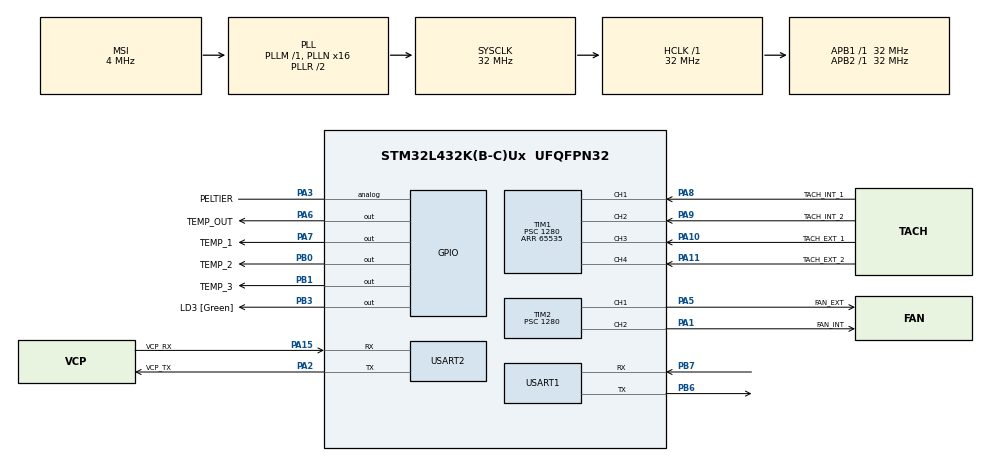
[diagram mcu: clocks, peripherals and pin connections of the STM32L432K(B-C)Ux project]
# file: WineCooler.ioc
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Mcu.Family=STM32L4
Mcu.Name=STM32L432K(B-C)Ux
Mcu.Package=UFQFPN32
NVIC.PriorityGroup=NVIC_PRIORITYGROUP_4
NVIC.TIM2_IRQn=true\:0\:0\:false\:false\:true\:true
NVIC.TIM6_DAC_IRQn=true\:0\:0\:false\:false\:true\:false
NVIC.TimeBase=TIM6_DAC_IRQn
NVIC.TimeBaseIP=TIM6
NVIC.USART1_IRQn=true\:0\:0\:false\:false\:true\:true
PA0.GPIO_Label=MCO [High speed clock in]
PA0.Mode=HSE-External-Clock-Source-for-LittleOrca
PA0.Signal=RCC_CK_IN
PA1.GPIO_Label=FAN_INT
PA1.GPIO_PuPd=GPIO_PULLUP
PA1.GPIO_Speed=GPIO_SPEED_FREQ_VERY_HIGH
PA1.Signal=S_TIM2_CH2
PA10.GPIO_Label=TACH_EXT_1
PA10.GPIO_Speed=GPIO_SPEED_FREQ_VERY_HIGH
PA10.Signal=S_TIM1_CH3
PA11.GPIO_Label=TACH_EXT_2
PA11.GPIO_Speed=GPIO_SPEED_FREQ_VERY_HIGH
PA11.Signal=S_TIM1_CH4
PA13\ (JTMS-SWDIO).GPIO_Label=SWDIO
PA13\ (JTMS-SWDIO).Mode=Serial_Wire
PA13\ (JTMS-SWDIO).Signal=SYS_JTMS-SWDIO
PA14\ (JTCK-SWCLK).GPIO_Label=SWCLK
PA14\ (JTCK-SWCLK).Mode=Serial_Wire
PA14\ (JTCK-SWCLK).Signal=SYS_JTCK-SWCLK
PA15\ (JTDI).GPIO_Label=VCP_RX
PA15\ (JTDI).Mode=Asynchronous
PA15\ (JTDI).Signal=USART2_RX
PA2.GPIO_Label=VCP_TX
PA2.Mode=Asynchronous
PA2.Signal=USART2_TX
PA3.GPIO_Label=PELTIER
PA3.Signal=GPIO_Analog
PA5.GPIO_Label=FAN_EXT
PA5.GPIO_PuPd=GPIO_PULLUP
PA5.GPIO_Speed=GPIO_SPEED_FREQ_VERY_HIGH
PA5.Signal=S_TIM2_CH1
PA6.GPIO_Label=TEMP_OUT
PA6.GPIO_Speed=GPIO_SPEED_FREQ_VERY_HIGH
PA6.Signal=GPIO_Output
PA7.GPIO_Label=TEMP_1
PA7.GPIO_Speed=GPIO_SPEED_FREQ_VERY_HIGH
PA7.Signal=GPIO_Output
PA8.GPIO_Label=TACH_INT_1
PA8.GPIO_Speed=GPIO_SPEED_FREQ_VERY_HIGH
PA8.Signal=S_TIM1_CH1
PA9.GPIO_Label=TACH_INT_2
PA9.GPIO_Speed=GPIO_SPEED_FREQ_VERY_HIGH
PA9.Signal=S_TIM1_CH2
PB0.GPIO_Label=TEMP_2
PB0.GPIO_Speed=GPIO_SPEED_FREQ_VERY_HIGH
PB0.Signal=GPIO_Output
PB1.GPIO_Label=TEMP_3
PB1.GPIO_Speed=GPIO_SPEED_FREQ_VERY_HIGH
PB1.Signal=GPIO_Output
PB3\ (JTDO-TRACESWO).GPIO_Label=LD3 [Green]
PB3\ (JTDO-TRACESWO).Signal=GPIO_Output
PB6.Mode=Asynchronous
PB6.Signal=USART1_TX
PB7.Mode=Asynchronous
PB7.Signal=USART1_RX
PC14-OSC32_IN\ (PC14).Mode=LSE-External-Oscillator
PC14-OSC32_IN\ (PC14).Signal=RCC_OSC32_IN
PC15-OSC32_OUT\ (PC15).Mode=LSE-External-Oscillator
PC15-OSC32_OUT\ (PC15).Signal=RCC_OSC32_OUT
ProjectManager.HeapSize=0x200
ProjectManager.StackSize=0x400
ProjectManager.TargetToolchain=SW4STM32
RCC.AHBFreq_Value=32000000
RCC.APB1Freq_Value=32000000
RCC.APB1TimFreq_Value=32000000
RCC.APB2Freq_Value=32000000
RCC.APB2TimFreq_Value=32000000
RCC.CortexFreq_Value=32000000
RCC.HCLKFreq_Value=32000000
RCC.HSE_VALUE=8000000
RCC.HSI16_VALUE=16000000
RCC.HSI48_VALUE=48000000
RCC.HSI_VALUE=16000000
RCC.MSI_VALUE=4000000
RCC.PLLMUL=RCC_PLLMUL_4
RCC.PLLN=16
RCC.SYSCLKFreq_VALUE=32000000
RCC.SYSCLKSource=RCC_SYSCLKSOURCE_PLLCLK
RCC.VCOOutputFreq_Value=64000000
SH.S_TIM1_CH1.0=TIM1_CH1,Input_Capture1_from_TI1
SH.S_TIM1_CH2.0=TIM1_CH2,Input_Capture2_from_TI2
SH.S_TIM1_CH3.0=TIM1_CH3,Input_Capture3_from_TI3
SH.S_TIM1_CH4.0=TIM1_CH4,Input_Capture4_from_TI4
SH.S_TIM2_CH1.0=TIM2_CH1,PWM Generation1 CH1
SH.S_TIM2_CH2.0=TIM2_CH2,PWM Generation2 CH2
TIM1.Channel-Input_Capture1_from_TI1=TIM_CHANNEL_1
TIM1.Channel-Input_Capture2_from_TI2=TIM_CHANNEL_2
TIM1.Channel-Input_Capture3_from_TI3=TIM_CHANNEL_3
TIM1.Channel-Input_Capture4_from_TI4=TIM_CHANNEL_4
TIM1.Period=65535
TIM1.Prescaler=1280
TIM2.Channel-PWM\ Generation1\ CH1=TIM_CHANNEL_1
TIM2.Channel-PWM\ Generation2\ CH2=TIM_CHANNEL_2
TIM2.OCFastMode_PWM-PWM\ Generation1\ CH1=TIM_OCFAST_ENABLE
TIM2.OCFastMode_PWM-PWM\ Generation2\ CH2=TIM_OCFAST_ENABLE
TIM2.Period=1000
TIM2.Prescaler=1280
TIM2.Pulse-PWM\ Generation1\ CH1=800
TIM2.Pulse-PWM\ Generation2\ CH2=800
USART1.VirtualMode-Asynchronous=VM_ASYNC
USART2.VirtualMode-Asynchronous=VM_ASYNC
VP_SYS_VS_tim6.Mode=TIM6
VP_TIM1_VS_ClockSourceINT.Mode=Internal
VP_TIM2_VS_ClockSourceINT.Mode=Internal
board=NUCLEO-L432KC

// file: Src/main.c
/**
  ******************************************************************************
  * @file           : main.c
  * @brief          : Main program body
  ******************************************************************************
  ** This notice applies to any and all portions of this file
  * that are not between comment pairs USER CODE BEGIN and
  * USER CODE END. Other portions of this file, whether
  * inserted by the user or by software development tools
  * are owned by their respective copyright owners.
  *
  * COPYRIGHT(c) 2018 STMicroelectronics
  *
  * Redistribution and use in source and binary forms, with or without modification,
  * are permitted provided that the following conditions are met:
  *   1. Redistributions of source code must retain the above copyright notice,
  *      this list of conditions and the following disclaimer.
  *   2. Redistributions in binary form must reproduce the above copyright notice,
  *      this list of conditions and the following disclaimer in the documentation
  *      and/or other materials provided with the distribution.
  *   3. Neither the name of STMicroelectronics nor the names of its contributors
  *      may be used to endorse or promote products derived from this software
  *      without specific prior written permission.
  *
  * THIS SOFTWARE IS PROVIDED BY THE COPYRIGHT HOLDERS AND CONTRIBUTORS "AS IS"
  * AND ANY EXPRESS OR IMPLIED WARRANTIES, INCLUDING, BUT NOT LIMITED TO, THE
  * IMPLIED WARRANTIES OF MERCHANTABILITY AND FITNESS FOR A PARTICULAR PURPOSE ARE
  * DISCLAIMED. IN NO EVENT SHALL THE COPYRIGHT HOLDER OR CONTRIBUTORS BE LIABLE
  * FOR ANY DIRECT, INDIRECT, INCIDENTAL, SPECIAL, EXEMPLARY, OR CONSEQUENTIAL
  * DAMAGES (INCLUDING, BUT NOT LIMITED TO, PROCUREMENT OF SUBSTITUTE GOODS OR
  * SERVICES; LOSS OF USE, DATA, OR PROFITS; OR BUSINESS INTERRUPTION) HOWEVER
  * CAUSED AND ON ANY THEORY OF LIABILITY, WHETHER IN CONTRACT, STRICT LIABILITY,
  * OR TORT (INCLUDING NEGLIGENCE OR OTHERWISE) ARISING IN ANY WAY OUT OF THE USE
  * OF THIS SOFTWARE, EVEN IF ADVISED OF THE POSSIBILITY OF SUCH DAMAGE.
  *
  ******************************************************************************
  */
#include "main.h"
#include "stm32l4xx_hal.h"
#include "tim.h"
#include "usart.h"
#include "gpio.h"

#include "WineCooler.hpp"

/* USER CODE BEGIN PV */
/* Private variables ---------------------------------------------------------*/

/* USER CODE END PV */

void SystemClock_Config(void);

/* USER CODE BEGIN PFP */
/* Private function prototypes -----------------------------------------------*/

/* USER CODE END PFP */

/* USER CODE BEGIN 0 */
void uart_tx(uint8_t* buffer, uint8_t buffer_length) {
	HAL_UART_Transmit(&huart1, buffer, buffer_length, HAL_MAX_DELAY);
}

uint8_t uart_rx(void) {
	return 0;
}

void wine_cooler_task(void (*uart_tx)(uint8_t*, uint8_t), uint8_t (*uart_rx)(void)) {

}
/* USER CODE END 0 */

int main(void)
{

  /* MCU Configuration----------------------------------------------------------*/

  /* Reset of all peripherals, Initializes the Flash interface and the Systick. */
  HAL_Init();

  /* Configure the system clock */
  SystemClock_Config();

  /* Initialize all configured peripherals */
  MX_GPIO_Init();
  MX_TIM1_Init();
  MX_TIM2_Init();
  MX_USART1_UART_Init();
  MX_USART2_UART_Init();
  /* USER CODE BEGIN 2 */
  wine_cooler_task(uart_tx, uart_rx);
  /* USER CODE END 2 */

  /* Infinite loop */
  while (1)
  {

  }

}

void SystemClock_Config(void)
{

  RCC_OscInitTypeDef RCC_OscInitStruct;
  RCC_ClkInitTypeDef RCC_ClkInitStruct;
  RCC_PeriphCLKInitTypeDef PeriphClkInit;

    /**Configure LSE Drive Capability
    */
  HAL_PWR_EnableBkUpAccess();

  __HAL_RCC_LSEDRIVE_CONFIG(RCC_LSEDRIVE_LOW);

    /**Initializes the CPU, AHB and APB busses clocks
    */
  RCC_OscInitStruct.OscillatorType = RCC_OSCILLATORTYPE_LSE|RCC_OSCILLATORTYPE_MSI;
  RCC_OscInitStruct.LSEState = RCC_LSE_ON;
  RCC_OscInitStruct.MSIState = RCC_MSI_ON;
  RCC_OscInitStruct.MSICalibrationValue = 0;
  RCC_OscInitStruct.MSIClockRange = RCC_MSIRANGE_6;
  RCC_OscInitStruct.PLL.PLLState = RCC_PLL_ON;
  RCC_OscInitStruct.PLL.PLLSource = RCC_PLLSOURCE_MSI;
  RCC_OscInitStruct.PLL.PLLM = 1;
  RCC_OscInitStruct.PLL.PLLN = 16;
  RCC_OscInitStruct.PLL.PLLP = RCC_PLLP_DIV7;
  RCC_OscInitStruct.PLL.PLLQ = RCC_PLLQ_DIV2;
  RCC_OscInitStruct.PLL.PLLR = RCC_PLLR_DIV2;
  if (HAL_RCC_OscConfig(&RCC_OscInitStruct) != HAL_OK)
  {
    _Error_Handler(__FILE__, __LINE__);
  }

    /**Initializes the CPU, AHB and APB busses clocks
    */
  RCC_ClkInitStruct.ClockType = RCC_CLOCKTYPE_HCLK|RCC_CLOCKTYPE_SYSCLK
                              |RCC_CLOCKTYPE_PCLK1|RCC_CLOCKTYPE_PCLK2;
  RCC_ClkInitStruct.SYSCLKSource = RCC_SYSCLKSOURCE_PLLCLK;
  RCC_ClkInitStruct.AHBCLKDivider = RCC_SYSCLK_DIV1;
  RCC_ClkInitStruct.APB1CLKDivider = RCC_HCLK_DIV1;
  RCC_ClkInitStruct.APB2CLKDivider = RCC_HCLK_DIV1;

  if (HAL_RCC_ClockConfig(&RCC_ClkInitStruct, FLASH_LATENCY_1) != HAL_OK)
  {
    _Error_Handler(__FILE__, __LINE__);
  }

  PeriphClkInit.PeriphClockSelection = RCC_PERIPHCLK_USART1|RCC_PERIPHCLK_USART2;
  PeriphClkInit.Usart1ClockSelection = RCC_USART1CLKSOURCE_PCLK2;
  PeriphClkInit.Usart2ClockSelection = RCC_USART2CLKSOURCE_PCLK1;
  if (HAL_RCCEx_PeriphCLKConfig(&PeriphClkInit) != HAL_OK)
  {
    _Error_Handler(__FILE__, __LINE__);
  }

    /**Configure the main internal regulator output voltage
    */
  if (HAL_PWREx_ControlVoltageScaling(PWR_REGULATOR_VOLTAGE_SCALE1) != HAL_OK)
  {
    _Error_Handler(__FILE__, __LINE__);
  }

    /**Configure the Systick interrupt time
    */
  HAL_SYSTICK_Config(HAL_RCC_GetHCLKFreq()/1000);

    /**Configure the Systick
    */
  HAL_SYSTICK_CLKSourceConfig(SYSTICK_CLKSOURCE_HCLK);

    /**Enable MSI Auto calibration
    */
  HAL_RCCEx_EnableMSIPLLMode();

  /* SysTick_IRQn interrupt configuration */
  HAL_NVIC_SetPriority(SysTick_IRQn, 0, 0);
}

void HAL_TIM_PeriodElapsedCallback(TIM_HandleTypeDef *htim)
{
  if (htim->Instance == TIM6) {
    HAL_IncTick();
  }
}

void _Error_Handler(char *file, int line)
{
  while(1)
  {
  }
}

/************************ (C) COPYRIGHT STMicroelectronics *****END OF FILE****/
